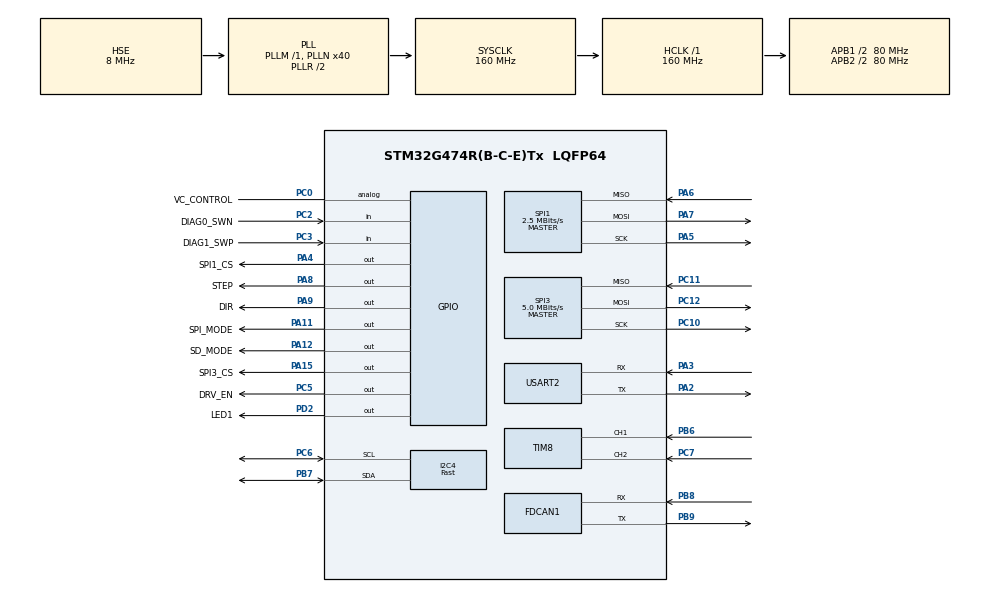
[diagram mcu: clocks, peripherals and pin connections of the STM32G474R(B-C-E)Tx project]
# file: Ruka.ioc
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Dma.I2C4_RX.0.Direction=DMA_PERIPH_TO_MEMORY
Dma.I2C4_RX.0.EventEnable=DISABLE
Dma.I2C4_RX.0.Instance=DMA1_Channel1
Dma.I2C4_RX.0.MemDataAlignment=DMA_MDATAALIGN_BYTE
Dma.I2C4_RX.0.MemInc=DMA_MINC_ENABLE
Dma.I2C4_RX.0.Mode=DMA_NORMAL
Dma.I2C4_RX.0.PeriphDataAlignment=DMA_PDATAALIGN_BYTE
Dma.I2C4_RX.0.PeriphInc=DMA_PINC_DISABLE
Dma.I2C4_RX.0.Polarity=HAL_DMAMUX_REQ_GEN_RISING
Dma.I2C4_RX.0.Priority=DMA_PRIORITY_LOW
Dma.I2C4_RX.0.RequestNumber=1
Dma.I2C4_RX.0.SignalID=NONE
Dma.I2C4_RX.0.SyncEnable=DISABLE
Dma.I2C4_RX.0.SyncPolarity=HAL_DMAMUX_SYNC_NO_EVENT
Dma.I2C4_RX.0.SyncRequestNumber=1
Dma.I2C4_RX.0.SyncSignalID=NONE
Dma.I2C4_TX.1.Direction=DMA_MEMORY_TO_PERIPH
Dma.I2C4_TX.1.EventEnable=DISABLE
Dma.I2C4_TX.1.Instance=DMA1_Channel2
Dma.I2C4_TX.1.MemDataAlignment=DMA_MDATAALIGN_BYTE
Dma.I2C4_TX.1.MemInc=DMA_MINC_ENABLE
Dma.I2C4_TX.1.Mode=DMA_NORMAL
Dma.I2C4_TX.1.PeriphDataAlignment=DMA_PDATAALIGN_BYTE
Dma.I2C4_TX.1.PeriphInc=DMA_PINC_DISABLE
Dma.I2C4_TX.1.Polarity=HAL_DMAMUX_REQ_GEN_RISING
Dma.I2C4_TX.1.Priority=DMA_PRIORITY_LOW
Dma.I2C4_TX.1.RequestNumber=1
Dma.I2C4_TX.1.SignalID=NONE
Dma.I2C4_TX.1.SyncEnable=DISABLE
Dma.I2C4_TX.1.SyncPolarity=HAL_DMAMUX_SYNC_NO_EVENT
Dma.I2C4_TX.1.SyncRequestNumber=1
Dma.I2C4_TX.1.SyncSignalID=NONE
Dma.Request0=I2C4_RX
Dma.Request1=I2C4_TX
FDCAN1.AutoRetransmission=ENABLE
FDCAN1.CalculateBaudRateNominal=1000000
FDCAN1.CalculateTimeBitNominal=1000
FDCAN1.CalculateTimeQuantumNominal=25.0
FDCAN1.DataPrescaler=4
FDCAN1.DataSyncJumpWidth=1
FDCAN1.DataTimeSeg1=2
FDCAN1.DataTimeSeg2=2
FDCAN1.ExtFiltersNbr=3
FDCAN1.FrameFormat=FDCAN_FRAME_FD_BRS
FDCAN1.NominalPrescaler=4
FDCAN1.NominalTimeSeg1=29
FDCAN1.NominalTimeSeg2=10
FDCAN1.StdFiltersNbr=0
FDCAN1.TransmitPause=ENABLE
I2C4.CustomTiming=Disabled
I2C4.I2C_Fall_Time=0
I2C4.I2C_Rise_Time=0
I2C4.I2C_Speed_Mode=I2C_Fast
I2C4.NoStretchMode=I2C_NOSTRETCH_DISABLE
I2C4.Timing=0x00702991
Mcu.Family=STM32G4
Mcu.Name=STM32G474R(B-C-E)Tx
Mcu.Package=LQFP64
NVIC.DMA1_Channel1_IRQn=true\:0\:0\:false\:false\:true\:false\:true\:true
NVIC.DMA1_Channel2_IRQn=true\:0\:0\:false\:false\:true\:false\:true\:true
NVIC.I2C4_ER_IRQn=true\:0\:0\:false\:false\:true\:true\:true\:true
NVIC.I2C4_EV_IRQn=true\:0\:0\:false\:false\:true\:true\:true\:true
NVIC.PriorityGroup=NVIC_PRIORITYGROUP_4
NVIC.SPI1_IRQn=true\:0\:0\:false\:false\:true\:true\:true\:true
NVIC.TIM6_DAC_IRQn=true\:0\:0\:false\:false\:true\:true\:true\:true
NVIC.TIM7_DAC_IRQn=true\:0\:0\:false\:false\:true\:true\:true\:true
NVIC.USART2_IRQn=true\:0\:0\:false\:false\:true\:true\:true\:true
PA11.GPIO_Label=SPI_MODE
PA11.Signal=GPIO_Output
PA12.GPIO_Label=SD_MODE
PA12.Signal=GPIO_Output
PA15.GPIO_Label=SPI3_CS
PA15.Signal=GPIO_Output
PA2.Mode=Asynchronous
PA2.Signal=USART2_TX
PA3.Mode=Asynchronous
PA3.Signal=USART2_RX
PA4.GPIO_Label=SPI1_CS
PA4.Signal=GPIO_Output
PA5.Mode=Full_Duplex_Master
PA5.Signal=SPI1_SCK
PA6.Mode=Full_Duplex_Master
PA6.Signal=SPI1_MISO
PA7.Mode=Full_Duplex_Master
PA7.Signal=SPI1_MOSI
PA8.GPIO_Label=STEP
PA8.Signal=GPIO_Output
PA9.GPIO_Label=DIR
PA9.Signal=GPIO_Output
PB6.Signal=S_TIM8_CH1
PB7.GPIO_Pu=GPIO_NOPULL
PB7.GPIO_Speed=GPIO_SPEED_FREQ_LOW
PB7.Mode=I2C
PB7.Signal=I2C4_SDA
PB8-BOOT0.Mode=FDCAN_Activate
PB8-BOOT0.Signal=FDCAN1_RX
PB9.Mode=FDCAN_Activate
PB9.Signal=FDCAN1_TX
PC0.GPIO_Label=VC_CONTROL
PC0.Signal=GPIO_Analog
PC10.Mode=Full_Duplex_Master
PC10.Signal=SPI3_SCK
PC11.Mode=Full_Duplex_Master
PC11.Signal=SPI3_MISO
PC12.Mode=Full_Duplex_Master
PC12.Signal=SPI3_MOSI
PC2.GPIO_Label=DIAG0_SWN
PC2.Signal=GPIO_Input
PC3.GPIO_Label=DIAG1_SWP
PC3.Signal=GPIO_Input
PC5.GPIO_Label=DRV_EN
PC5.Signal=GPIO_Output
PC6.GPIO_Pu=GPIO_NOPULL
PC6.GPIO_Speed=GPIO_SPEED_FREQ_LOW
PC6.Mode=I2C
PC6.Signal=I2C4_SCL
PC7.Signal=S_TIM8_CH2
PD2.GPIO_Label=LED1
PD2.Signal=GPIO_Output
PF0-OSC_IN.Mode=HSE-External-Oscillator
PF0-OSC_IN.Signal=RCC_OSC_IN
PF1-OSC_OUT.Mode=HSE-External-Oscillator
PF1-OSC_OUT.Signal=RCC_OSC_OUT
ProjectManager.HeapSize=0x200
ProjectManager.StackSize=0x400
ProjectManager.TargetToolchain=STM32CubeIDE
RCC.ADC12Freq_Value=160000000
RCC.ADC345Freq_Value=160000000
RCC.AHBFreq_Value=160000000
RCC.APB1CLKDivider=RCC_HCLK_DIV2
RCC.APB1Freq_Value=80000000
RCC.APB1TimFreq_Value=160000000
RCC.APB2CLKDivider=RCC_HCLK_DIV2
RCC.APB2Freq_Value=80000000
RCC.APB2TimFreq_Value=160000000
RCC.CortexFreq_Value=160000000
RCC.EXTERNAL_CLOCK_VALUE=12288000
RCC.FDCANCLockSelection=RCC_FDCANCLKSOURCE_PLL
RCC.HCLKFreq_Value=160000000
RCC.HSE_VALUE=8000000
RCC.HSI48_VALUE=48000000
RCC.HSI_VALUE=16000000
RCC.LSE_VALUE=32768
RCC.PLLN=40
RCC.PLLSourceVirtual=RCC_PLLSOURCE_HSE
RCC.SYSCLKFreq_VALUE=160000000
RCC.SYSCLKSource=RCC_SYSCLKSOURCE_PLLCLK
RCC.USBFreq_Value=160000000
RCC.VCOOutputFreq_Value=320000000
SH.S_TIM8_CH1.0=TIM8_CH1,Encoder_Interface
SH.S_TIM8_CH2.0=TIM8_CH2,Encoder_Interface
SPI1.BaudRatePrescaler=SPI_BAUDRATEPRESCALER_32
SPI1.CLKPhase=SPI_PHASE_2EDGE
SPI1.CLKPolarity=SPI_POLARITY_HIGH
SPI1.CalculateBaudRate=2.5 MBits/s
SPI1.DataSize=SPI_DATASIZE_8BIT
SPI1.Direction=SPI_DIRECTION_2LINES
SPI1.Mode=SPI_MODE_MASTER
SPI1.VirtualType=VM_MASTER
SPI3.BaudRatePrescaler=SPI_BAUDRATEPRESCALER_16
SPI3.CLKPhase=SPI_PHASE_2EDGE
SPI3.CalculateBaudRate=5.0 MBits/s
SPI3.DataSize=SPI_DATASIZE_16BIT
SPI3.Direction=SPI_DIRECTION_2LINES
SPI3.Mode=SPI_MODE_MASTER
SPI3.VirtualType=VM_MASTER
TIM6.AutoReloadPreload=TIM_AUTORELOAD_PRELOAD_DISABLE
TIM6.PeriodNoDither=9999
TIM6.Prescaler=159
TIM7.PeriodNoDither=9999
TIM7.Prescaler=1599
USART2.VirtualMode-Asynchronous=VM_ASYNC
VP_SYS_VS_DBSignals.Mode=DisableDeadBatterySignals
VP_TIM6_VS_ClockSourceINT.Mode=Enable_Timer
VP_TIM7_VS_ClockSourceINT.Mode=Enable_Timer
board=custom

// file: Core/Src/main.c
/* USER CODE BEGIN Header */
/**
  ******************************************************************************
  * @file           : main.c
  * @brief          : Main program body
  ******************************************************************************
  * @attention
  *
  * Copyright (c) 2024 STMicroelectronics.
  * All rights reserved.
  *
  * This software is licensed under terms that can be found in the LICENSE file
  * in the root directory of this software component.
  * If no LICENSE file comes with this software, it is provided AS-IS.
  *
  ******************************************************************************
  */
/* USER CODE END Header */
#include "main.h"
#include "dma.h"
#include "fdcan.h"
#include "i2c.h"
#include "spi.h"
#include "tim.h"
#include "usart.h"
#include "gpio.h"

/* USER CODE BEGIN Includes */
#include "main_impl.h"

//#include "joint_config.h"

/* USER CODE END Includes */

void SystemClock_Config(void);

int main(void)
{

  /* MCU Configuration--------------------------------------------------------*/

  /* Reset of all peripherals, Initializes the Flash interface and the Systick. */
  HAL_Init();

  /* Configure the system clock */
  SystemClock_Config();

  /* Initialize all configured peripherals */
  MX_GPIO_Init();
  MX_DMA_Init();
  MX_FDCAN1_Init();
  MX_I2C4_Init();
  MX_USART2_UART_Init();
  MX_SPI1_Init();
  MX_SPI3_Init();
  MX_TIM8_Init();
  MX_TIM7_Init();
  MX_TIM6_Init();
  /* USER CODE BEGIN 2 */
  HAL_TIM_Base_Start_IT(&htim7);
  HAL_TIM_Base_Start_IT(&htim6);

  /* USER CODE END 2 */

  /* Infinite loop */
  /* USER CODE BEGIN WHILE */

  main_cpp();

  while (1)
  {

  }
    /* USER CODE END WHILE */

}

void SystemClock_Config(void)
{
  RCC_OscInitTypeDef RCC_OscInitStruct = {0};
  RCC_ClkInitTypeDef RCC_ClkInitStruct = {0};

  /** Configure the main internal regulator output voltage
  */
  HAL_PWREx_ControlVoltageScaling(PWR_REGULATOR_VOLTAGE_SCALE1_BOOST);

  /** Initializes the RCC Oscillators according to the specified parameters
  * in the RCC_OscInitTypeDef structure.
  */
  RCC_OscInitStruct.OscillatorType = RCC_OSCILLATORTYPE_HSE;
  RCC_OscInitStruct.HSEState = RCC_HSE_ON;
  RCC_OscInitStruct.PLL.PLLState = RCC_PLL_ON;
  RCC_OscInitStruct.PLL.PLLSource = RCC_PLLSOURCE_HSE;
  RCC_OscInitStruct.PLL.PLLM = RCC_PLLM_DIV1;
  RCC_OscInitStruct.PLL.PLLN = 40;
  RCC_OscInitStruct.PLL.PLLP = RCC_PLLP_DIV2;
  RCC_OscInitStruct.PLL.PLLQ = RCC_PLLQ_DIV2;
  RCC_OscInitStruct.PLL.PLLR = RCC_PLLR_DIV2;
  if (HAL_RCC_OscConfig(&RCC_OscInitStruct) != HAL_OK)
  {
    Error_Handler();
  }

  /** Initializes the CPU, AHB and APB buses clocks
  */
  RCC_ClkInitStruct.ClockType = RCC_CLOCKTYPE_HCLK|RCC_CLOCKTYPE_SYSCLK
                              |RCC_CLOCKTYPE_PCLK1|RCC_CLOCKTYPE_PCLK2;
  RCC_ClkInitStruct.SYSCLKSource = RCC_SYSCLKSOURCE_PLLCLK;
  RCC_ClkInitStruct.AHBCLKDivider = RCC_SYSCLK_DIV1;
  RCC_ClkInitStruct.APB1CLKDivider = RCC_HCLK_DIV2;
  RCC_ClkInitStruct.APB2CLKDivider = RCC_HCLK_DIV2;

  if (HAL_RCC_ClockConfig(&RCC_ClkInitStruct, FLASH_LATENCY_4) != HAL_OK)
  {
    Error_Handler();
  }
}

void Error_Handler(void)
{
  __disable_irq();
  while (1)
  {
  }
}
